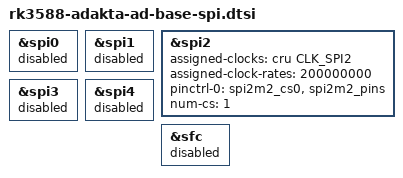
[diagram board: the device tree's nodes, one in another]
// SPDX-License-Identifier: (GPL-2.0+ OR MIT)
/*
 * Copyright (c) 2024 Adakta, Ltd.
 *
 */

&spi0 {
	status = "disabled";
};

&spi1 {
	status = "disabled";
};

&spi2 {
	assigned-clocks = <&cru CLK_SPI2>;
	assigned-clock-rates = <200000000>;

	pinctrl-names = "default";
	pinctrl-0 = <&spi2m2_cs0 &spi2m2_pins>;
	num-cs = <1>;
	status = "okay";
};

&spi3 {
	status = "disabled";
};

&spi4 {
	status = "disabled";
};

&sfc {
	status = "disabled";
};
